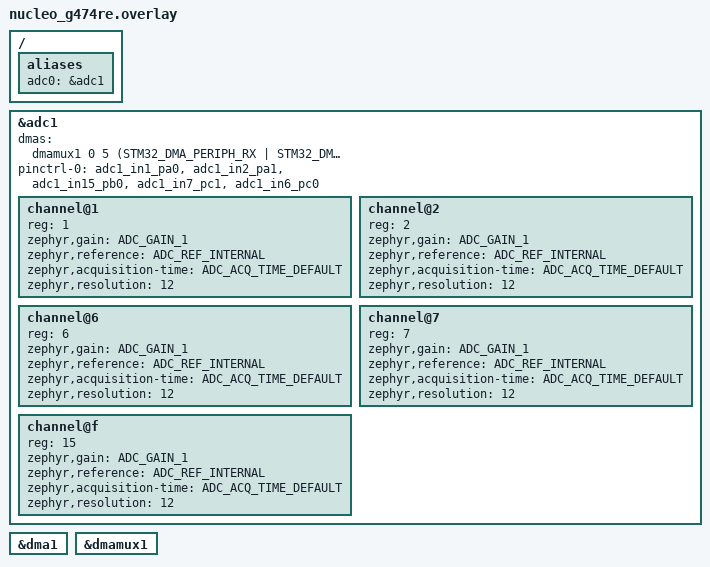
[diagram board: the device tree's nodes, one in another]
/*
 * SPDX-FileCopyrightText: Copyright The Zephyr Project Contributors
 * SPDX-FileCopyrightText: Copyright (c) 2026 Caglayan Dokme <caglayandokme@gmail.com>
 * SPDX-License-Identifier: Apache-2.0
 */

/ {
	aliases {
		/* Alias created to keep the sample code board agnostic */
		adc0 = &adc1;
	};
};

&adc1 {
	dmas = <&dmamux1 0 5 (STM32_DMA_PERIPH_RX | STM32_DMA_MEM_16BITS |
			      STM32_DMA_PERIPH_16BITS)>;
	dma-names = "dmamux";

	pinctrl-0 = <&adc1_in1_pa0 &adc1_in2_pa1 &adc1_in15_pb0
		     &adc1_in7_pc1 &adc1_in6_pc0>;
	pinctrl-names = "default";
	#address-cells = <1>;
	#size-cells = <0>;

	channel@1 {
		reg = <1>;
		zephyr,gain = "ADC_GAIN_1";
		zephyr,reference = "ADC_REF_INTERNAL";
		zephyr,acquisition-time = <ADC_ACQ_TIME_DEFAULT>;
		zephyr,resolution = <12>;
	};

	channel@2 {
		reg = <2>;
		zephyr,gain = "ADC_GAIN_1";
		zephyr,reference = "ADC_REF_INTERNAL";
		zephyr,acquisition-time = <ADC_ACQ_TIME_DEFAULT>;
		zephyr,resolution = <12>;
	};

	channel@6 {
		reg = <6>;
		zephyr,gain = "ADC_GAIN_1";
		zephyr,reference = "ADC_REF_INTERNAL";
		zephyr,acquisition-time = <ADC_ACQ_TIME_DEFAULT>;
		zephyr,resolution = <12>;
	};

	channel@7 {
		reg = <7>;
		zephyr,gain = "ADC_GAIN_1";
		zephyr,reference = "ADC_REF_INTERNAL";
		zephyr,acquisition-time = <ADC_ACQ_TIME_DEFAULT>;
		zephyr,resolution = <12>;
	};

	channel@f {
		reg = <15>;
		zephyr,gain = "ADC_GAIN_1";
		zephyr,reference = "ADC_REF_INTERNAL";
		zephyr,acquisition-time = <ADC_ACQ_TIME_DEFAULT>;
		zephyr,resolution = <12>;
	};
};

&dma1 {
	status = "okay";
};

&dmamux1 {
	status = "okay";
};

